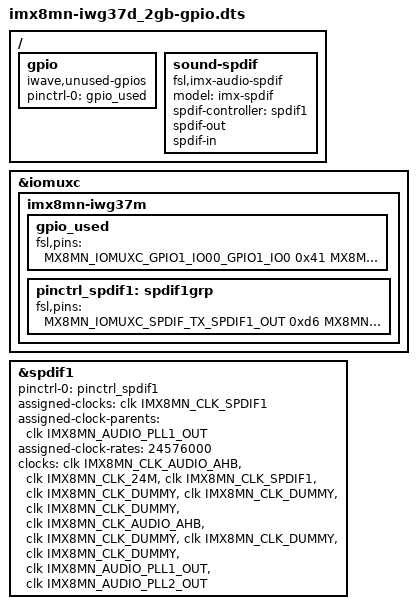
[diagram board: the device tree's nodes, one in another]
/*
 * Copyright (C) 2020 iWave System Technologies Pvt Ltd.
 *
 * This program is free software; you can redistribute it and/or
 * modify it under the terms of the GNU General Public License
 * as published by the Free Software Foundation; either version 2
 * of the License, or (at your option) any later version.
 *
 * This program is distributed in the hope that it will be useful,
 * but WITHOUT ANY WARRANTY; without even the implied warranty of
 * MERCHANTABILITY or FITNESS FOR A PARTICULAR PURPOSE.  See the
 * GNU General Public License for more details.
 */

/dts-v1/;

#include "imx8mn-iwg37d_2gb.dts"

/ {
	gpio { /* GPIO: Setting Unused GPIOs as input pins */
                compatible = "iwave,unused-gpios";
                pinctrl-names = "default";
                pinctrl-0 = <&gpio_used>;
                status = "okay";
        };

	sound-spdif {
                compatible = "fsl,imx-audio-spdif";
                model = "imx-spdif";
                spdif-controller = <&spdif1>;
                spdif-out;
                spdif-in;
        };

};

&iomuxc {
        pinctrl-names = "default";

        imx8mn-iwg37m {

			gpio_used: gpio_used {
                                fsl,pins = <
                                        /* GPIO: Unused GPIO IOMUX Pin Configuration */
                                        MX8MN_IOMUXC_GPIO1_IO00_GPIO1_IO0               0x41
                        	        MX8MN_IOMUXC_GPIO1_IO10_GPIO1_IO10              0x41
                	                MX8MN_IOMUXC_GPIO1_IO11_GPIO1_IO11              0x41
        	                        MX8MN_IOMUXC_GPIO1_IO14_GPIO1_IO14              0x41
	                                MX8MN_IOMUXC_GPIO1_IO15_GPIO1_IO15              0x41
					>;
                                };

			pinctrl_spdif1: spdif1grp {
                       		fsl,pins = <
                                	MX8MN_IOMUXC_SPDIF_TX_SPDIF1_OUT                0xd6
                               		MX8MN_IOMUXC_SPDIF_RX_SPDIF1_IN                 0xd6
					MX8MN_IOMUXC_SPDIF_EXT_CLK_SPDIF1_EXT_CLK       0xd6 
                       			>;
                		};
		    };
};

&spdif1 {
        pinctrl-names = "default";
        pinctrl-0 = <&pinctrl_spdif1>;
        assigned-clocks = <&clk IMX8MN_CLK_SPDIF1>;
        assigned-clock-parents = <&clk IMX8MN_AUDIO_PLL1_OUT>;
        assigned-clock-rates = <24576000>;
        clocks = <&clk IMX8MN_CLK_AUDIO_AHB>, <&clk IMX8MN_CLK_24M>,
                <&clk IMX8MN_CLK_SPDIF1>, <&clk IMX8MN_CLK_DUMMY>,
                <&clk IMX8MN_CLK_DUMMY>, <&clk IMX8MN_CLK_DUMMY>,
                <&clk IMX8MN_CLK_AUDIO_AHB>, <&clk IMX8MN_CLK_DUMMY>,
                <&clk IMX8MN_CLK_DUMMY>, <&clk IMX8MN_CLK_DUMMY>,
                <&clk IMX8MN_AUDIO_PLL1_OUT>, <&clk IMX8MN_AUDIO_PLL2_OUT>;
        clock-names = "core", "rxtx0", "rxtx1", "rxtx2", "rxtx3",
                "rxtx4", "rxtx5", "rxtx6", "rxtx7", "spba", "pll8k", "pll11k";
        status = "okay";
};
